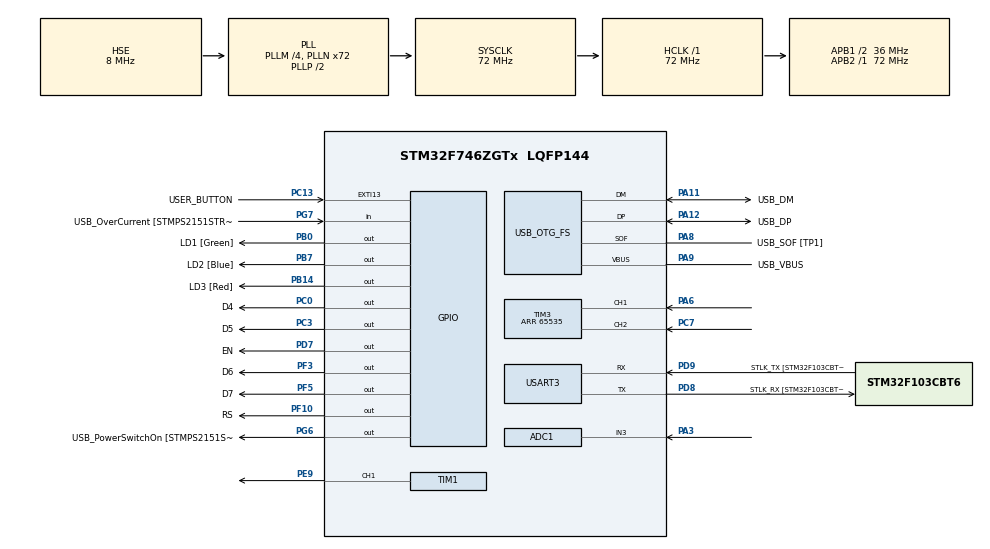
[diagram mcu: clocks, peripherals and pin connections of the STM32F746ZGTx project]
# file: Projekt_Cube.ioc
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ADC1.Channel-0\#ChannelRegularConversion=ADC_CHANNEL_3
ADC1.NbrOfConversionFlag=1
ADC1.Rank-0\#ChannelRegularConversion=1
ADC1.SamplingTime-0\#ChannelRegularConversion=ADC_SAMPLETIME_3CYCLES
ADC1.master=1
Mcu.Family=STM32F7
Mcu.Name=STM32F746ZGTx
Mcu.Package=LQFP144
NVIC.EXTI15_10_IRQn=true\:0\:0\:false\:false\:true\:true\:true
NVIC.PriorityGroup=NVIC_PRIORITYGROUP_4
NVIC.TIM1_BRK_TIM9_IRQn=true\:4\:0\:true\:false\:true\:true\:true
NVIC.TIM4_IRQn=true\:5\:0\:true\:false\:true\:true\:true
NVIC.USART3_IRQn=true\:3\:0\:true\:false\:true\:true\:true
PA1.GPIO_Label=RMII_REF_CLK [LAN8742A-CZ-TR_REFCLK0]
PA1.Signal=ETH_REF_CLK
PA10.GPIO_Label=USB_ID
PA10.Signal=USB_OTG_FS_ID
PA11.GPIO_Label=USB_DM
PA11.Mode=Device_Only
PA11.Signal=USB_OTG_FS_DM
PA12.GPIO_Label=USB_DP
PA12.Mode=Device_Only
PA12.Signal=USB_OTG_FS_DP
PA13.GPIO_Label=TMS
PA13.Mode=Serial_Wire
PA13.Signal=SYS_JTMS-SWDIO
PA14.GPIO_Label=TCK
PA14.Mode=Serial_Wire
PA14.Signal=SYS_JTCK-SWCLK
PA2.GPIO_Label=RMII_MDIO [LAN8742A-CZ-TR_MDIO]
PA2.Signal=ETH_MDIO
PA3.Signal=ADCx_IN3
PA6.Signal=S_TIM3_CH1
PA7.GPIO_Label=RMII_CRS_DV [LAN8742A-CZ-TR_CRS_DV]
PA7.Signal=ETH_CRS_DV
PA8.GPIO_Label=USB_SOF [TP1]
PA8.Mode=Activate_SOF_FS
PA8.Signal=USB_OTG_FS_SOF
PA9.GPIO_Label=USB_VBUS
PA9.Mode=Activate_VBUS
PA9.Signal=USB_OTG_FS_VBUS
PB0.GPIO_Label=LD1 [Green]
PB0.Signal=GPIO_Output
PB13.GPIO_Label=RMII_TXD1 [LAN8742A-CZ-TR_TXD1]
PB13.Signal=ETH_TXD1
PB14.GPIO_Label=LD3 [Red]
PB14.Signal=GPIO_Output
PB3.GPIO_Label=SW0
PB3.Signal=SYS_JTDO-SWO
PB7.GPIO_Label=LD2 [Blue]
PB7.Signal=GPIO_Output
PC0.GPIO_Label=D4
PC0.Signal=GPIO_Output
PC1.GPIO_Label=RMII_MDC [LAN8742A-CZ-TR_MDC]
PC1.Signal=ETH_MDC
PC13.GPIO_Label=USER_BUTTON
PC13.Signal=GPXTI13
PC14/OSC32_IN.Mode=LSE-External-Oscillator
PC14/OSC32_IN.Signal=RCC_OSC32_IN
PC15/OSC32_OUT.Mode=LSE-External-Oscillator
PC15/OSC32_OUT.Signal=RCC_OSC32_OUT
PC3.GPIO_Label=D5
PC3.Signal=GPIO_Output
PC4.GPIO_Label=RMII_RXD0 [LAN8742A-CZ-TR_RXD0]
PC4.Signal=ETH_RXD0
PC5.GPIO_Label=RMII_RXD1 [LAN8742A-CZ-TR_RXD1]
PC5.Signal=ETH_RXD1
PC7.Signal=S_TIM3_CH2
PD7.GPIO_Label=EN
PD7.Signal=GPIO_Output
PD8.GPIO_Label=STLK_RX [STM32F103CBT6_PA3]
PD8.Mode=Asynchronous
PD8.Signal=USART3_TX
PD9.GPIO_Label=STLK_TX [STM32F103CBT6_PA2]
PD9.Mode=Asynchronous
PD9.Signal=USART3_RX
PE9.Signal=S_TIM1_CH1
PF10.GPIO_Label=RS
PF10.Signal=GPIO_Output
PF3.GPIO_Label=D6
PF3.Signal=GPIO_Output
PF5.GPIO_Label=D7
PF5.Signal=GPIO_Output
PG11.GPIO_Label=RMII_TX_EN [LAN8742A-CZ-TR_TXEN]
PG11.Signal=ETH_TX_EN
PG13.GPIO_Label=RMII_TXD0 [LAN8742A-CZ-TR_TXD0]
PG13.Signal=ETH_TXD0
PG6.GPIO_Label=USB_PowerSwitchOn [STMPS2151STR_EN]
PG6.Signal=GPIO_Output
PG7.GPIO_Label=USB_OverCurrent [STMPS2151STR_FAULT]
PG7.Signal=GPIO_Input
PH0/OSC_IN.GPIO_Label=MCO [STM32F103CBT6_PA8]
PH0/OSC_IN.Mode=HSE-External-Clock-Source
PH0/OSC_IN.Signal=RCC_OSC_IN
PH1/OSC_OUT.Mode=HSE-External-Clock-Source
PH1/OSC_OUT.Signal=RCC_OSC_OUT
ProjectManager.HeapSize=0x200
ProjectManager.StackSize=0x400
ProjectManager.TargetToolchain=STM32CubeIDE
RCC.48MHZClocksFreq_Value=24000000
RCC.AHBFreq_Value=72000000
RCC.APB1CLKDivider=RCC_HCLK_DIV2
RCC.APB1Freq_Value=36000000
RCC.APB1TimFreq_Value=72000000
RCC.APB2Freq_Value=72000000
RCC.APB2TimFreq_Value=72000000
RCC.CortexFreq_Value=72000000
RCC.HCLKFreq_Value=72000000
RCC.HSE_VALUE=8000000
RCC.HSI_VALUE=16000000
RCC.PLLM=4
RCC.PLLMUL=RCC_PLL_MUL9
RCC.PLLN=72
RCC.PLLQ=3
RCC.PRESCALERUSB=RCC_USBCLKSOURCE_PLL_DIV1_5
RCC.SYSCLKFreq_VALUE=72000000
RCC.SYSCLKSource=RCC_SYSCLKSOURCE_PLLCLK
RCC.SYSCLKSourceVirtual=RCC_SYSCLKSOURCE_PLLCLK
RCC.USBFreq_Value=48000000
RCC.VCOOutputFreq_Value=144000000
SH.ADCx_IN3.0=ADC1_IN3,IN3
SH.S_TIM1_CH1.0=TIM1_CH1,PWM Generation1 CH1
SH.S_TIM3_CH1.0=TIM3_CH1,Encoder_Interface
SH.S_TIM3_CH2.0=TIM3_CH2,Encoder_Interface
TIM1.Channel-PWM\ Generation1\ CH1=TIM_CHANNEL_1
TIM1.Period=999
TIM1.Prescaler=71
TIM3.AutoReloadPreload=TIM_AUTORELOAD_PRELOAD_ENABLE
TIM3.EncoderMode=TIM_ENCODERMODE_TI12
TIM3.IC1Filter=0
TIM3.IC1Polarity=TIM_ICPOLARITY_FALLING
TIM3.IC2Filter=0
TIM3.IC2Polarity=TIM_ICPOLARITY_FALLING
TIM3.Period=65535
TIM4.CounterMode=TIM_COUNTERMODE_UP
TIM4.Period=49
TIM4.Prescaler=7199
TIM9.Period=99
TIM9.Prescaler=7199
USART3.VirtualMode-Asynchronous=VM_ASYNC
USB_OTG_FS.VirtualMode=Device_Only
VP_TIM1_VS_ClockSourceINT.Mode=Internal
VP_TIM4_VS_ClockSourceINT.Mode=Internal
VP_TIM9_VS_ClockSourceINT.Mode=Internal
board=NUCLEO-F746ZG

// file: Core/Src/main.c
/* USER CODE BEGIN Header */
/**
  ******************************************************************************
  * @file           : main.c
  * @brief          : Main program body
  ******************************************************************************
  * @attention
  *
  * <h2><center>&copy; Copyright (c) 2022 STMicroelectronics.
  * All rights reserved.</center></h2>
  *
  * This software component is licensed by ST under BSD 3-Clause license,
  * the "License"; You may not use this file except in compliance with the
  * License. You may obtain a copy of the License at:
  *                        opensource.org/licenses/BSD-3-Clause
  *
  ******************************************************************************
  */
/* USER CODE END Header */
#include "main.h"
#include "adc.h"
#include "tim.h"
#include "usart.h"
#include "usb_otg.h"
#include "gpio.h"

/* USER CODE BEGIN Includes */
#include "pid.h"
#include <stdlib.h>
/* USER CODE END Includes */

/* USER CODE BEGIN PV */
//Lcd_PortType ports[] =
//		{ D4_GPIO_Port, D5_GPIO_Port, D6_GPIO_Port, D7_GPIO_Port };
//
//Lcd_PinType pins[] = { D4_Pin, D5_Pin, D6_Pin, D7_Pin };
//
//Lcd_HandleTypeDef lcd;

/* USER CODE END PV */

void SystemClock_Config(void);

int main(void)
{

  /* MCU Configuration--------------------------------------------------------*/

  /* Reset of all peripherals, Initializes the Flash interface and the Systick. */
  HAL_Init();

  /* Configure the system clock */
  SystemClock_Config();

  /* Initialize all configured peripherals */
  MX_GPIO_Init();
  MX_USART3_UART_Init();
  MX_USB_OTG_FS_PCD_Init();
  MX_TIM4_Init();
  MX_TIM3_Init();
  MX_TIM1_Init();
  MX_ADC1_Init();
  MX_TIM9_Init();
  /* USER CODE BEGIN 2 */

  HAL_TIM_PWM_Start(&htim1, TIM_CHANNEL_1);
  // Initialized PID
  InitPID();

  // Initializing peripherials
  HAL_TIM_Base_Start_IT(&htim9);
  HAL_UART_Receive_IT(&huart3, usart_Message, 5);
  HAL_TIM_Base_Start_IT(&htim4);
  HAL_TIM_Encoder_Start(&htim3, TIM_CHANNEL_1);
  HAL_TIM_Encoder_Start(&htim3, TIM_CHANNEL_2);

  /* USER CODE END 2 */

  /* Infinite loop */
  /* USER CODE BEGIN WHILE */

	while (1) {
		//HAL_Delay(300);
//	  HAL_UART_Transmit(&huart3, (uint8_t*)msg, strlen(msg), 1000);
    /* USER CODE END WHILE */

	}
}

void SystemClock_Config(void)
{
  RCC_OscInitTypeDef RCC_OscInitStruct = {0};
  RCC_ClkInitTypeDef RCC_ClkInitStruct = {0};
  RCC_PeriphCLKInitTypeDef PeriphClkInitStruct = {0};

  /** Configure LSE Drive Capability
  */
  HAL_PWR_EnableBkUpAccess();
  /** Configure the main internal regulator output voltage
  */
  __HAL_RCC_PWR_CLK_ENABLE();
  __HAL_PWR_VOLTAGESCALING_CONFIG(PWR_REGULATOR_VOLTAGE_SCALE3);
  /** Initializes the RCC Oscillators according to the specified parameters
  * in the RCC_OscInitTypeDef structure.
  */
  RCC_OscInitStruct.OscillatorType = RCC_OSCILLATORTYPE_HSE;
  RCC_OscInitStruct.HSEState = RCC_HSE_BYPASS;
  RCC_OscInitStruct.PLL.PLLState = RCC_PLL_ON;
  RCC_OscInitStruct.PLL.PLLSource = RCC_PLLSOURCE_HSE;
  RCC_OscInitStruct.PLL.PLLM = 4;
  RCC_OscInitStruct.PLL.PLLN = 72;
  RCC_OscInitStruct.PLL.PLLP = RCC_PLLP_DIV2;
  RCC_OscInitStruct.PLL.PLLQ = 3;
  if (HAL_RCC_OscConfig(&RCC_OscInitStruct) != HAL_OK)
  {
    Error_Handler();
  }
  /** Initializes the CPU, AHB and APB buses clocks
  */
  RCC_ClkInitStruct.ClockType = RCC_CLOCKTYPE_HCLK|RCC_CLOCKTYPE_SYSCLK
                              |RCC_CLOCKTYPE_PCLK1|RCC_CLOCKTYPE_PCLK2;
  RCC_ClkInitStruct.SYSCLKSource = RCC_SYSCLKSOURCE_PLLCLK;
  RCC_ClkInitStruct.AHBCLKDivider = RCC_SYSCLK_DIV1;
  RCC_ClkInitStruct.APB1CLKDivider = RCC_HCLK_DIV2;
  RCC_ClkInitStruct.APB2CLKDivider = RCC_HCLK_DIV1;

  if (HAL_RCC_ClockConfig(&RCC_ClkInitStruct, FLASH_LATENCY_2) != HAL_OK)
  {
    Error_Handler();
  }
  PeriphClkInitStruct.PeriphClockSelection = RCC_PERIPHCLK_USART3|RCC_PERIPHCLK_CLK48;
  PeriphClkInitStruct.Usart3ClockSelection = RCC_USART3CLKSOURCE_PCLK1;
  PeriphClkInitStruct.Clk48ClockSelection = RCC_CLK48SOURCE_PLL;
  if (HAL_RCCEx_PeriphCLKConfig(&PeriphClkInitStruct) != HAL_OK)
  {
    Error_Handler();
  }
}

void Error_Handler(void)
{
  __disable_irq();
  while (1)
  {
  }
}

/************************ (C) COPYRIGHT STMicroelectronics *****END OF FILE****/
